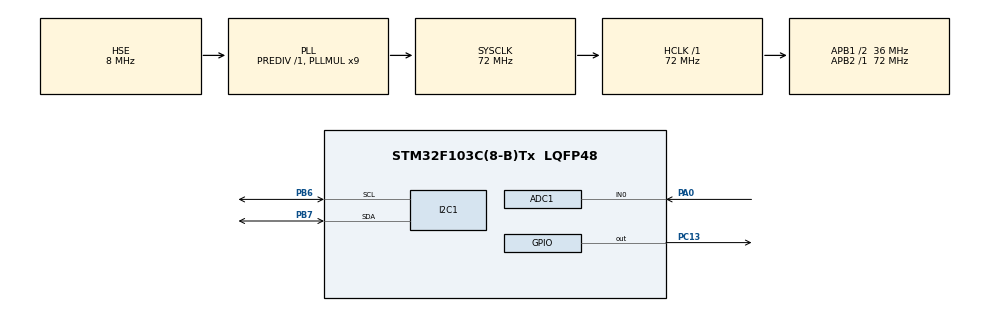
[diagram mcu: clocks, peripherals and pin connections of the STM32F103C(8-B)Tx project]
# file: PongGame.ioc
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ADC1.Channel-0\#ChannelRegularConversion=ADC_CHANNEL_0
ADC1.Channel-1\#ChannelInjectedConversion=ADC_CHANNEL_0
ADC1.ContinuousConvMode=ENABLE
ADC1.InjNumberOfConversion=1
ADC1.InjectedOffset-1\#ChannelInjectedConversion=0
ADC1.NbrOfConversionFlag=1
ADC1.Rank-0\#ChannelRegularConversion=1
ADC1.Rank-1\#ChannelInjectedConversion=1
ADC1.SamplingTime-0\#ChannelRegularConversion=ADC_SAMPLETIME_1CYCLE_5
ADC1.SamplingTime-1\#ChannelInjectedConversion=ADC_SAMPLETIME_1CYCLE_5
ADC1.master=1
ADC2.Channel-0\#ChannelRegularConversion=ADC_CHANNEL_0
ADC2.Channel-1\#ChannelInjectedConversion=ADC_CHANNEL_0
ADC2.ContinuousConvMode=ENABLE
ADC2.InjNumberOfConversion=1
ADC2.InjectedOffset-1\#ChannelInjectedConversion=0
ADC2.NbrOfConversionFlag=1
ADC2.Rank-0\#ChannelRegularConversion=1
ADC2.Rank-1\#ChannelInjectedConversion=1
ADC2.SamplingTime-0\#ChannelRegularConversion=ADC_SAMPLETIME_1CYCLE_5
ADC2.SamplingTime-1\#ChannelInjectedConversion=ADC_SAMPLETIME_1CYCLE_5
I2C1.I2C_Mode=I2C_Fast
Mcu.Family=STM32F1
Mcu.Name=STM32F103C(8-B)Tx
Mcu.Package=LQFP48
NVIC.PriorityGroup=NVIC_PRIORITYGROUP_4
PA0-WKUP.Signal=ADCx_IN0
PB6.Mode=I2C
PB6.Signal=I2C1_SCL
PB7.Mode=I2C
PB7.Signal=I2C1_SDA
PC13-TAMPER-RTC.Signal=GPIO_Output
PD0-OSC_IN.Mode=HSE-External-Oscillator
PD0-OSC_IN.Signal=RCC_OSC_IN
PD1-OSC_OUT.Mode=HSE-External-Oscillator
PD1-OSC_OUT.Signal=RCC_OSC_OUT
ProjectManager.HeapSize=0x200
ProjectManager.StackSize=0x400
ProjectManager.TargetToolchain=MDK-ARM V4
RCC.ADCPresc=RCC_ADCPCLK2_DIV6
RCC.AHBFreq_Value=72000000
RCC.APB1CLKDivider=RCC_HCLK_DIV2
RCC.APB1Freq_Value=36000000
RCC.APB1TimCLKDivider=1
RCC.APB1TimFreq_Value=36000000
RCC.APB2Freq_Value=72000000
RCC.APB2TimFreq_Value=72000000
RCC.HCLKFreq_Value=72000000
RCC.HSIState=RCC_HSI_ON
RCC.PLLMUL=RCC_PLL_MUL9
RCC.PLLSourceVirtual=RCC_PLLSOURCE_HSE
RCC.SYSCLKFreq_VALUE=72000000
RCC.SYSCLKSource=RCC_SYSCLKSOURCE_PLLCLK
RCC.USBFreq_Value=72000000
SH.ADCx_IN0.0=ADC1_IN0,IN0
SH.ADCx_IN0.1=ADC2_IN0,IN0
board=PongGame

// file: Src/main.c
/**
  ******************************************************************************
  * File Name          : main.c
  * Description        : Main program body
  ******************************************************************************
  *
  * COPYRIGHT(c) 2020 STMicroelectronics
  *
  * Redistribution and use in source and binary forms, with or without modification,
  * are permitted provided that the following conditions are met:
  *   1. Redistributions of source code must retain the above copyright notice,
  *      this list of conditions and the following disclaimer.
  *   2. Redistributions in binary form must reproduce the above copyright notice,
  *      this list of conditions and the following disclaimer in the documentation
  *      and/or other materials provided with the distribution.
  *   3. Neither the name of STMicroelectronics nor the names of its contributors
  *      may be used to endorse or promote products derived from this software
  *      without specific prior written permission.
  *
  * THIS SOFTWARE IS PROVIDED BY THE COPYRIGHT HOLDERS AND CONTRIBUTORS "AS IS"
  * AND ANY EXPRESS OR IMPLIED WARRANTIES, INCLUDING, BUT NOT LIMITED TO, THE
  * IMPLIED WARRANTIES OF MERCHANTABILITY AND FITNESS FOR A PARTICULAR PURPOSE ARE
  * DISCLAIMED. IN NO EVENT SHALL THE COPYRIGHT HOLDER OR CONTRIBUTORS BE LIABLE
  * FOR ANY DIRECT, INDIRECT, INCIDENTAL, SPECIAL, EXEMPLARY, OR CONSEQUENTIAL
  * DAMAGES (INCLUDING, BUT NOT LIMITED TO, PROCUREMENT OF SUBSTITUTE GOODS OR
  * SERVICES; LOSS OF USE, DATA, OR PROFITS; OR BUSINESS INTERRUPTION) HOWEVER
  * CAUSED AND ON ANY THEORY OF LIABILITY, WHETHER IN CONTRACT, STRICT LIABILITY,
  * OR TORT (INCLUDING NEGLIGENCE OR OTHERWISE) ARISING IN ANY WAY OUT OF THE USE
  * OF THIS SOFTWARE, EVEN IF ADVISED OF THE POSSIBILITY OF SUCH DAMAGE.
  *
  ******************************************************************************
  */
#include "stm32f1xx_hal.h"
#include "ssd1306.h"
#include "Pong_Game.h"

ADC_HandleTypeDef hadc1;
ADC_HandleTypeDef hadc2;

I2C_HandleTypeDef hi2c1;

/* USER CODE BEGIN PV */
/* Private variables ---------------------------------------------------------*/

/* USER CODE END PV */

void SystemClock_Config(void);
static void MX_GPIO_Init(void);
static void MX_ADC1_Init(void);
static void MX_ADC2_Init(void);
static void MX_I2C1_Init(void);

/* USER CODE BEGIN PFP */
/* Private function prototypes -----------------------------------------------*/

/* USER CODE END PFP */

uint32_t AdcVal1;
uint32_t AdcVal2;
int8_t Paddle1_direction;
int8_t Paddle2_direction;
extern Pong Game_Pong;
extern Paddle Game_Paddle1;
extern Paddle Game_Paddle2;

int main(void)
{

  /* MCU Configuration----------------------------------------------------------*/

  /* Reset of all peripherals, Initializes the Flash interface and the Systick. */
  HAL_Init();

  /* Configure the system clock */
  SystemClock_Config();

  /* Initialize all configured peripherals */
  MX_GPIO_Init();
  MX_ADC1_Init();
  MX_ADC2_Init();
  MX_I2C1_Init();

  /* USER CODE BEGIN 2 */
	HAL_ADC_Start(&hadc1);
	HAL_ADC_Start(&hadc2);
  /* USER CODE END 2 */

  /* Infinite loop */
  /* USER CODE BEGIN WHILE */

	AdcVal1 = AdcVal2 = 0;
	LCD_Init();
	HAL_Delay(50);
	LCD_Fill(Black);
	LCD_UpdateScreen();
	Paddle1_direction = 0;
	Paddle2_direction = 0;

  while (1)
  {
		AdcVal1 = HAL_ADC_GetValue(&hadc1);
		AdcVal2 = HAL_ADC_GetValue(&hadc2);

		if(AdcVal1 < 1500){
			Paddle1_direction = PADDLE_DOWN;
		}else if(AdcVal1 < 2500){
			Paddle1_direction = PADDLE_FREEZE;
		}else{
			Paddle1_direction = PADDLE_UP;
		}

		if(AdcVal2 < 1500){
			Paddle2_direction = PADDLE_DOWN;
		}else if(AdcVal2 < 2500){
			Paddle2_direction = PADDLE_FREEZE;
		}else{
			Paddle2_direction = PADDLE_UP;
		}

		PongMove();
		PaddleMove(Paddle1_direction, Paddle2_direction);

		LCD_FillCircle(Game_Pong.X_pos,Game_Pong.Y_pos,Game_Pong.Radius,White);
		LCD_FillRect(Game_Paddle1.X_pos,Game_Paddle1.Y_pos,Game_Paddle1.Width,Game_Paddle1.Height,White);
		LCD_FillRect(Game_Paddle2.X_pos,Game_Paddle2.Y_pos,Game_Paddle2.Width,Game_Paddle2.Height,White);
		//LCD_DrawDotRect(0,0,128,32);
		LCD_UpdateScreen();
		LCD_Fill(Black);

		// Delay for adc conversion
		HAL_Delay(1);

  }
  /* USER CODE END 3 */

}

/** System Clock Configuration
*/
void SystemClock_Config(void)
{

  RCC_OscInitTypeDef RCC_OscInitStruct;
  RCC_ClkInitTypeDef RCC_ClkInitStruct;
  RCC_PeriphCLKInitTypeDef PeriphClkInit;

  RCC_OscInitStruct.OscillatorType = RCC_OSCILLATORTYPE_HSE;
  RCC_OscInitStruct.HSEState = RCC_HSE_ON;
  RCC_OscInitStruct.HSEPredivValue = RCC_HSE_PREDIV_DIV1;
  RCC_OscInitStruct.PLL.PLLState = RCC_PLL_ON;
  RCC_OscInitStruct.PLL.PLLSource = RCC_PLLSOURCE_HSE;
  RCC_OscInitStruct.PLL.PLLMUL = RCC_PLL_MUL9;
  HAL_RCC_OscConfig(&RCC_OscInitStruct);

  RCC_ClkInitStruct.ClockType = RCC_CLOCKTYPE_HCLK|RCC_CLOCKTYPE_SYSCLK
                              |RCC_CLOCKTYPE_PCLK1|RCC_CLOCKTYPE_PCLK2;
  RCC_ClkInitStruct.SYSCLKSource = RCC_SYSCLKSOURCE_PLLCLK;
  RCC_ClkInitStruct.AHBCLKDivider = RCC_SYSCLK_DIV1;
  RCC_ClkInitStruct.APB1CLKDivider = RCC_HCLK_DIV2;
  RCC_ClkInitStruct.APB2CLKDivider = RCC_HCLK_DIV1;
  HAL_RCC_ClockConfig(&RCC_ClkInitStruct, FLASH_LATENCY_2);

  PeriphClkInit.PeriphClockSelection = RCC_PERIPHCLK_ADC;
  PeriphClkInit.AdcClockSelection = RCC_ADCPCLK2_DIV6;
  HAL_RCCEx_PeriphCLKConfig(&PeriphClkInit);

  HAL_SYSTICK_Config(HAL_RCC_GetHCLKFreq()/1000);

  HAL_SYSTICK_CLKSourceConfig(SYSTICK_CLKSOURCE_HCLK);

  /* SysTick_IRQn interrupt configuration */
  HAL_NVIC_SetPriority(SysTick_IRQn, 0, 0);
}

/* ADC1 init function */
void MX_ADC1_Init(void)
{

  ADC_ChannelConfTypeDef sConfig;

    /**Common config
    */
  hadc1.Instance = ADC1;
  hadc1.Init.ScanConvMode = ADC_SCAN_DISABLE;
  hadc1.Init.ContinuousConvMode = ENABLE;
  hadc1.Init.DiscontinuousConvMode = DISABLE;
  hadc1.Init.ExternalTrigConv = ADC_SOFTWARE_START;
  hadc1.Init.DataAlign = ADC_DATAALIGN_RIGHT;
  hadc1.Init.NbrOfConversion = 1;
  HAL_ADC_Init(&hadc1);

    /**Configure Regular Channel
    */
  sConfig.Channel = ADC_CHANNEL_0;
  sConfig.Rank = 1;
  sConfig.SamplingTime = ADC_SAMPLETIME_1CYCLE_5;
  HAL_ADC_ConfigChannel(&hadc1, &sConfig);
}

/* ADC2 init function */
void MX_ADC2_Init(void)
{

  ADC_ChannelConfTypeDef sConfig;

    /**Common config
    */
  hadc2.Instance = ADC2;
  hadc2.Init.ScanConvMode = ADC_SCAN_DISABLE;
  hadc2.Init.ContinuousConvMode = ENABLE;
  hadc2.Init.DiscontinuousConvMode = DISABLE;
  hadc2.Init.ExternalTrigConv = ADC_SOFTWARE_START;
  hadc2.Init.DataAlign = ADC_DATAALIGN_RIGHT;
  hadc2.Init.NbrOfConversion = 1;
  HAL_ADC_Init(&hadc2);

    /**Configure Regular Channel
    */
  sConfig.Channel = ADC_CHANNEL_1;
  sConfig.Rank = 1;
  sConfig.SamplingTime = ADC_SAMPLETIME_1CYCLE_5;
  HAL_ADC_ConfigChannel(&hadc2, &sConfig);
}

/* I2C1 init function */
void MX_I2C1_Init(void)
{

  hi2c1.Instance = I2C1;
  hi2c1.Init.ClockSpeed = 400000;
  hi2c1.Init.DutyCycle = I2C_DUTYCYCLE_2;
  hi2c1.Init.OwnAddress1 = 0;
  hi2c1.Init.AddressingMode = I2C_ADDRESSINGMODE_7BIT;
  hi2c1.Init.DualAddressMode = I2C_DUALADDRESS_DISABLE;
  hi2c1.Init.OwnAddress2 = 0;
  hi2c1.Init.GeneralCallMode = I2C_GENERALCALL_DISABLE;
  hi2c1.Init.NoStretchMode = I2C_NOSTRETCH_DISABLE;
  HAL_I2C_Init(&hi2c1);

}

/** Configure pins as
        * Analog
        * Input
        * Output
        * EVENT_OUT
        * EXTI
*/
void MX_GPIO_Init(void)
{

  GPIO_InitTypeDef GPIO_InitStruct;

  /* GPIO Ports Clock Enable */
  __HAL_RCC_GPIOC_CLK_ENABLE();
  __HAL_RCC_GPIOD_CLK_ENABLE();
  __HAL_RCC_GPIOA_CLK_ENABLE();
  __HAL_RCC_GPIOB_CLK_ENABLE();

  /*Configure GPIO pin Output Level */
  HAL_GPIO_WritePin(GPIOC, GPIO_PIN_13, GPIO_PIN_RESET);

  /*Configure GPIO pin : PC13 */
  GPIO_InitStruct.Pin = GPIO_PIN_13;
  GPIO_InitStruct.Mode = GPIO_MODE_OUTPUT_PP;
  GPIO_InitStruct.Speed = GPIO_SPEED_FREQ_LOW;
  HAL_GPIO_Init(GPIOC, &GPIO_InitStruct);

}

/************************ (C) COPYRIGHT STMicroelectronics *****END OF FILE****/
